# CH32L103 register map
Vendor: WCH Ltd.; File version: 1.3
Registers are 32-bit, read-write, reset 0x0 unless marked. A register's access mark holds for its fields unless they carry their own. Offsets are from the block's base; [hi:lo] are bit positions; {n}, {i} and the like mark numbered series.

## AFIO — Alternate function I/O
Base 0x40010000
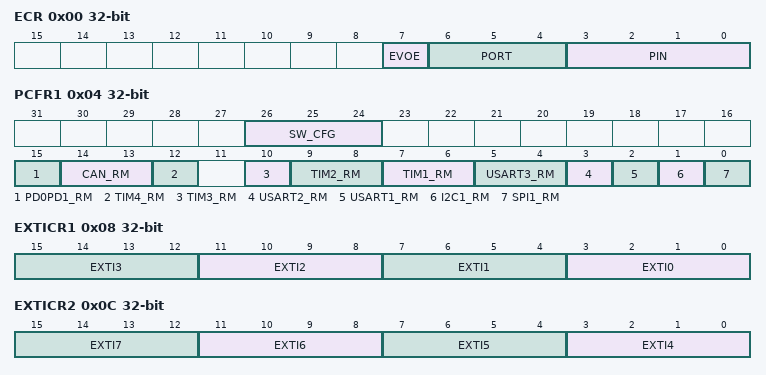
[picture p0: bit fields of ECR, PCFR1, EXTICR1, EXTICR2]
0x00 ECR — Event Control Register (AFIO_ECR)
  [7] EVOE — Event Output Enable
  [6:4] PORT — Port selection
  [3:0] PIN — Pin selection
0x04 PCFR1 access per field — AF remap and debug I/O configuration register 1 (AFIO_PCFR1)
  [26:24] SW_CFG wo — Serial wire JTAG configuration
  [15] PD0PD1_RM rw — Port D0/Port D1 mapping on OSCIN/OSCOUT
  [14:13] CAN_RM rw — CAN remapping
  [12] TIM4_RM rw — TIM4 remapping
  [10] TIM3_RM rw — TIM3 remapping
  [9:8] TIM2_RM rw — TIM2 remapping
  [7:6] TIM1_RM rw — TIM1 remapping
  [5:4] USART3_RM rw — USART3 remapping
  [3] USART2_RM rw — USART2 remapping
  [2] USART1_RM rw — USART1 remapping
  [1] I2C1_RM rw — I2C1 remapping
  [0] SPI1_RM rw — SPI1 remapping
0x08 EXTICR1 — External interrupt configuration register 1 (AFIO_EXTICR1)
  [4n+3:4n] EXTI{n} (n=0..3) — EXTI{n} configuration
0x0C EXTICR2 — External interrupt configuration register 2 (AFIO_EXTICR2)
  [4n-13:4n-16] EXTI{n} (n=4..7) — EXTI{n} configuration
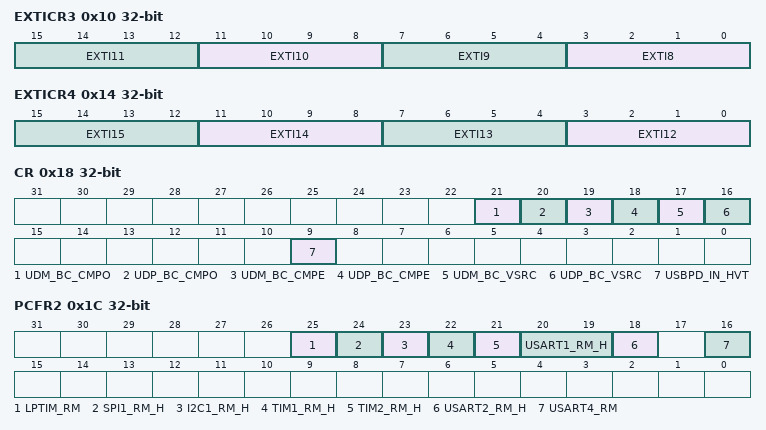
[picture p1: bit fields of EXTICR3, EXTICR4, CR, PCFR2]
0x10 EXTICR3 — External interrupt configuration register 3 (AFIO_EXTICR3)
  [4n-29:4n-32] EXTI{n} (n=8..11) — EXTI{n} configuration
0x14 EXTICR4 — External interrupt configuration register 4 (AFIO_EXTICR4)
  [4n-45:4n-48] EXTI{n} (n=12..15) — EXTI{n} configuration
0x18 CR access per field — AFIO control register (AFIO_CR)
  [21] UDM_BC_CMPO ro — PA11/UDM pin BC protocol comparator status
  [20] UDP_BC_CMPO ro — PA12/UDP pin BC protocol comparator status
  [19] UDM_BC_CMPE rw — PA11/UDM pin BC protocol comparator enable
  [18] UDP_BC_CMPE rw — PA12/UDP pin BC protocol comparator enable
  [17] UDM_BC_VSRC rw — PA11/UDM pin BC source voltage enable
  [16] UDP_BC_VSRC rw — PA12/UDP pin BC source voltage enable
  [9] USBPD_IN_HVT rw — PD pin PB6/PD7 High threshold input mode
0x1C PCFR2 — AF remap and debug I/O configuration register (AFIO_PCFR2)
  [25] LPTIM_RM — LPTIM remapping
  [24] SPI1_RM_H — SPI1 remapping
  [23] I2C1_RM_H — I2C1 remapping
  [22] TIM1_RM_H — TIM1 remapping
  [21] TIM2_RM_H — TIM2 remapping
  [20:19] USART1_RM_H — USART1 remapping
  [18] USART2_RM_H — USART2 remapping
  [16] USART4_RM — USART4 remapping

## EXTI
Base 0x40010400
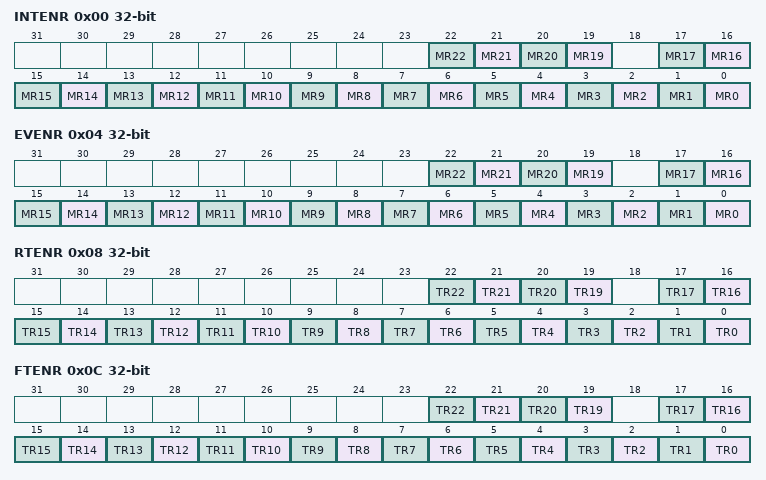
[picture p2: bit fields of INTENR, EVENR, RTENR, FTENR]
0x00 INTENR — Interrupt mask register (EXTI_INTENR)
  [n] MR{n} (n=19..22) — Interrupt Mask on line {n}
  [n] MR{n} (n=0..17) — Interrupt Mask on line {n}
0x04 EVENR — Event mask register (EXTI_EVENR)
  [n] MR{n} (n=19..22) — Event Mask on line {n}
  [n] MR{n} (n=0..17) — Event Mask on line {n}
0x08 RTENR — Rising Trigger selection register (EXTI_RTENR)
  [n] TR{n} (n=19..22) — Rising trigger event configuration of line {n}
  [n] TR{n} (n=0..17) — Rising trigger event configuration of line {n}
0x0C FTENR — Falling Trigger selection register (EXTI_FTENR)
  [n] TR{n} (n=19..22) — Falling trigger event configuration of line {n}
  [n] TR{n} (n=0..17) — Falling trigger event configuration of line {n}
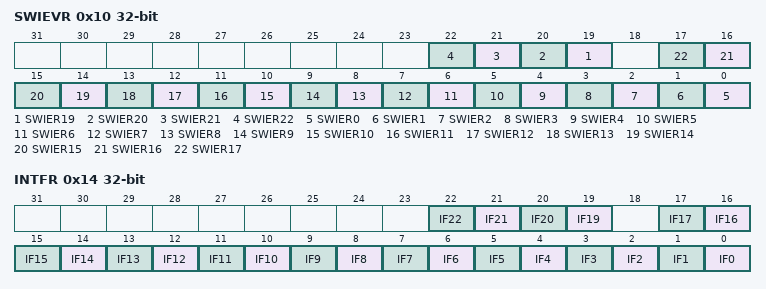
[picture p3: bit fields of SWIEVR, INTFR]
0x10 SWIEVR — Software interrupt event register (EXTI_SWIEVR)
  [n] SWIER{n} (n=19..22) — Software Interrupt on line {n}
  [n] SWIER{n} (n=0..17) — Software Interrupt on line {n}
0x14 INTFR — interrupt flag register (EXTI_INTFR)
  [n] IF{n} (n=19..22) — interrupt flag bit {n}
  [n] IF{n} (n=0..17) — interrupt flag bit {n}

## RTC — Real time clock
Base 0x40002800
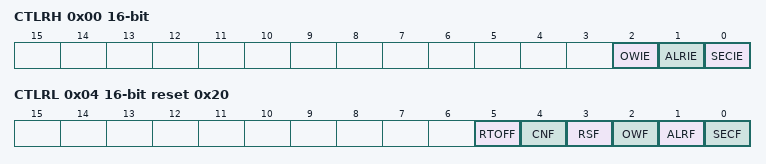
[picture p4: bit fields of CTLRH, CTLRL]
0x00 CTLRH 16-bit — RTC Control Register High
  [2] OWIE — Overflow interrupt Enable
  [1] ALRIE — Alarm interrupt Enable
  [0] SECIE — Second interrupt Enable
0x04 CTLRL 16-bit access per field reset 0x20 — RTC Control Register Low
  [5] RTOFF ro — RTC operation OFF
  [4] CNF rw — Configuration Flag
  [3] RSF rw — Registers Synchronized Flag
  [2] OWF rw — Overflow Flag
  [1] ALRF rw — Alarm Flag
  [0] SECF rw — Second Flag
0x08 PSCRH 16-bit wo — RTC Prescaler Load Register High
  [3:0] PRL
0x0C PSCRL 16-bit wo — RTC Prescaler Load Register Low
  [15:0] PRL — RTC Prescaler Divider Register Low
0x10 DIVH 16-bit ro — RTC Prescaler Divider Register High
  [3:0] DIV — RTC prescaler divider register high
0x14 DIVL 16-bit ro — RTC Prescaler Divider Register Low
  [15:0] DIV — RTC prescaler divider register Low
0x18 CNTH 16-bit — RTC Counter Register High
  [15:0] CNTH — RTC counter register high
0x1C CNTL 16-bit — RTC Counter Register Low
  [15:0] CNTL — RTC counter register Low
0x20 ALRMH 16-bit wo — RTC Alarm Register High
  [15:0] ALR — RTC alarm register high
0x24 ALRML 16-bit wo — RTC Alarm Register Low
  [15:0] ALR — RTC alarm register low
